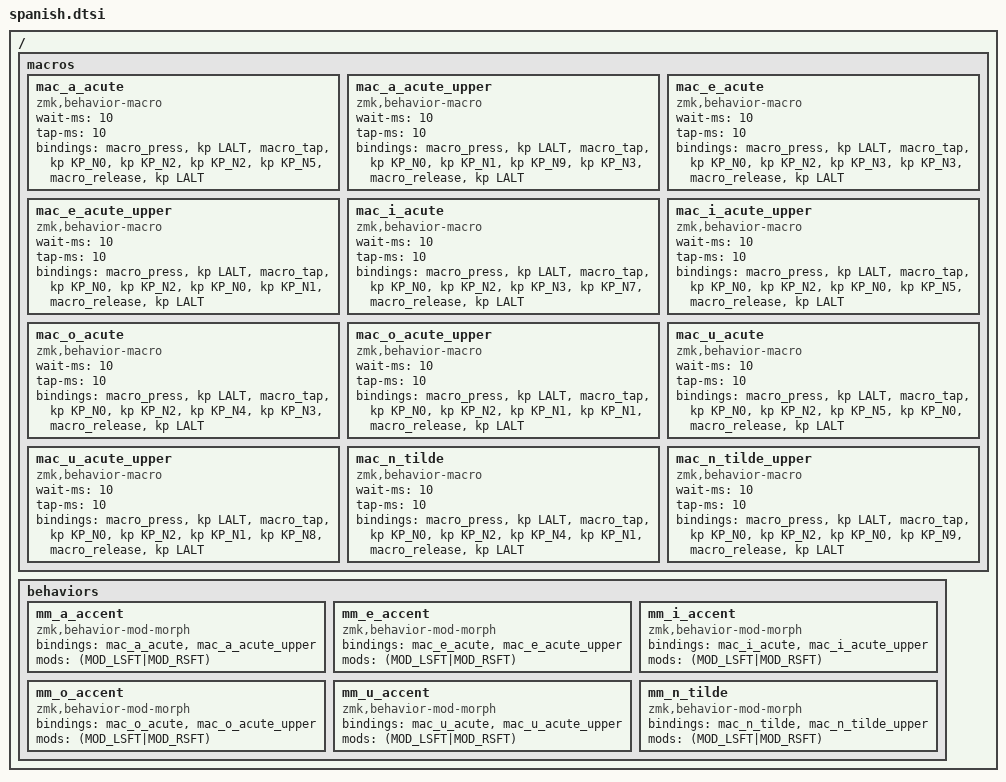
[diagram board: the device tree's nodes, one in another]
/*
 * Spanish — Accent macros + shift-aware mod-morphs
 *
 * Characters:  á/Á  é/É  í/Í  ó/Ó  ú/Ú  ñ/Ñ
 * Method:      Windows Alt Codes (ANSI 0xxx via numpad)
 *              Requires NumLock ON (activate once from Lower layer)
 *
 * Keymap refs: &mm_a_acute &mm_e_acute &mm_i_acute
 *              &mm_o_acute &mm_u_acute &mm_n_tilde
 */

/ {
    macros {
        mac_a_acute: mac_a_acute { compatible = "zmk,behavior-macro"; #binding-cells = <0>; wait-ms = <10>; tap-ms = <10>;
            bindings = <&macro_press &kp LALT>, <&macro_tap &kp KP_N0 &kp KP_N2 &kp KP_N2 &kp KP_N5>, <&macro_release &kp LALT>; };
        mac_a_acute_upper: mac_a_acute_upper { compatible = "zmk,behavior-macro"; #binding-cells = <0>; wait-ms = <10>; tap-ms = <10>;
            bindings = <&macro_press &kp LALT>, <&macro_tap &kp KP_N0 &kp KP_N1 &kp KP_N9 &kp KP_N3>, <&macro_release &kp LALT>; };

        mac_e_acute: mac_e_acute { compatible = "zmk,behavior-macro"; #binding-cells = <0>; wait-ms = <10>; tap-ms = <10>;
            bindings = <&macro_press &kp LALT>, <&macro_tap &kp KP_N0 &kp KP_N2 &kp KP_N3 &kp KP_N3>, <&macro_release &kp LALT>; };
        mac_e_acute_upper: mac_e_acute_upper { compatible = "zmk,behavior-macro"; #binding-cells = <0>; wait-ms = <10>; tap-ms = <10>;
            bindings = <&macro_press &kp LALT>, <&macro_tap &kp KP_N0 &kp KP_N2 &kp KP_N0 &kp KP_N1>, <&macro_release &kp LALT>; };

        mac_i_acute: mac_i_acute { compatible = "zmk,behavior-macro"; #binding-cells = <0>; wait-ms = <10>; tap-ms = <10>;
            bindings = <&macro_press &kp LALT>, <&macro_tap &kp KP_N0 &kp KP_N2 &kp KP_N3 &kp KP_N7>, <&macro_release &kp LALT>; };
        mac_i_acute_upper: mac_i_acute_upper { compatible = "zmk,behavior-macro"; #binding-cells = <0>; wait-ms = <10>; tap-ms = <10>;
            bindings = <&macro_press &kp LALT>, <&macro_tap &kp KP_N0 &kp KP_N2 &kp KP_N0 &kp KP_N5>, <&macro_release &kp LALT>; };

        mac_o_acute: mac_o_acute { compatible = "zmk,behavior-macro"; #binding-cells = <0>; wait-ms = <10>; tap-ms = <10>;
            bindings = <&macro_press &kp LALT>, <&macro_tap &kp KP_N0 &kp KP_N2 &kp KP_N4 &kp KP_N3>, <&macro_release &kp LALT>; };
        mac_o_acute_upper: mac_o_acute_upper { compatible = "zmk,behavior-macro"; #binding-cells = <0>; wait-ms = <10>; tap-ms = <10>;
            bindings = <&macro_press &kp LALT>, <&macro_tap &kp KP_N0 &kp KP_N2 &kp KP_N1 &kp KP_N1>, <&macro_release &kp LALT>; };

        mac_u_acute: mac_u_acute { compatible = "zmk,behavior-macro"; #binding-cells = <0>; wait-ms = <10>; tap-ms = <10>;
            bindings = <&macro_press &kp LALT>, <&macro_tap &kp KP_N0 &kp KP_N2 &kp KP_N5 &kp KP_N0>, <&macro_release &kp LALT>; };
        mac_u_acute_upper: mac_u_acute_upper { compatible = "zmk,behavior-macro"; #binding-cells = <0>; wait-ms = <10>; tap-ms = <10>;
            bindings = <&macro_press &kp LALT>, <&macro_tap &kp KP_N0 &kp KP_N2 &kp KP_N1 &kp KP_N8>, <&macro_release &kp LALT>; };

        mac_n_tilde: mac_n_tilde { compatible = "zmk,behavior-macro"; #binding-cells = <0>; wait-ms = <10>; tap-ms = <10>;
            bindings = <&macro_press &kp LALT>, <&macro_tap &kp KP_N0 &kp KP_N2 &kp KP_N4 &kp KP_N1>, <&macro_release &kp LALT>; };
        mac_n_tilde_upper: mac_n_tilde_upper { compatible = "zmk,behavior-macro"; #binding-cells = <0>; wait-ms = <10>; tap-ms = <10>;
            bindings = <&macro_press &kp LALT>, <&macro_tap &kp KP_N0 &kp KP_N2 &kp KP_N0 &kp KP_N9>, <&macro_release &kp LALT>; };
    };

    behaviors {
        mm_a_accent: mm_a_accent { compatible = "zmk,behavior-mod-morph"; #binding-cells = <0>;
            bindings = <&mac_a_acute>, <&mac_a_acute_upper>; mods = <(MOD_LSFT|MOD_RSFT)>; };
        mm_e_accent: mm_e_accent { compatible = "zmk,behavior-mod-morph"; #binding-cells = <0>;
            bindings = <&mac_e_acute>, <&mac_e_acute_upper>; mods = <(MOD_LSFT|MOD_RSFT)>; };
        mm_i_accent: mm_i_accent { compatible = "zmk,behavior-mod-morph"; #binding-cells = <0>;
            bindings = <&mac_i_acute>, <&mac_i_acute_upper>; mods = <(MOD_LSFT|MOD_RSFT)>; };
        mm_o_accent: mm_o_accent { compatible = "zmk,behavior-mod-morph"; #binding-cells = <0>;
            bindings = <&mac_o_acute>, <&mac_o_acute_upper>; mods = <(MOD_LSFT|MOD_RSFT)>; };
        mm_u_accent: mm_u_accent { compatible = "zmk,behavior-mod-morph"; #binding-cells = <0>;
            bindings = <&mac_u_acute>, <&mac_u_acute_upper>; mods = <(MOD_LSFT|MOD_RSFT)>; };
        mm_n_tilde: mm_n_tilde { compatible = "zmk,behavior-mod-morph"; #binding-cells = <0>;
            bindings = <&mac_n_tilde>, <&mac_n_tilde_upper>; mods = <(MOD_LSFT|MOD_RSFT)>; };
    };
};
